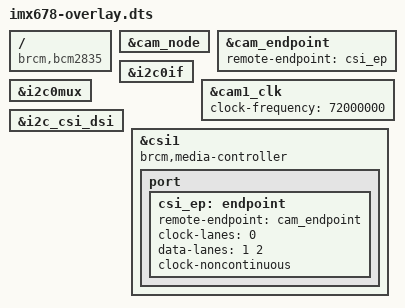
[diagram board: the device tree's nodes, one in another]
// SPDX-License-Identifier: GPL-2.0-only
// Definitions for imx678 camera module on VC I2C bus
/dts-v1/;
/plugin/;

#include <dt-bindings/gpio/gpio.h>

/{
	compatible = "brcm,bcm2835";

    fragment@2 {
		target = <&i2c0if>;
		__overlay__ {
			status = "okay";
		};
	};

    clk_frag: fragment@3 {
		target = <&cam1_clk>;
		__overlay__ {
			clock-frequency = <72000000>;
			status = "okay";
		};
	};

    fragment@4 {
		target = <&i2c0mux>;
		__overlay__ {
			status = "okay";
		};
	};

	i2c_frag: fragment@0 {
		target = <&i2c_csi_dsi>;
		__overlay__ {
			#address-cells = <1>;
			#size-cells = <0>;
			status = "okay";

			#include "imx678.dtsi"
		};
	};

	csi_frag: fragment@1 {
		target = <&csi1>;
		csi: __overlay__ {
			status = "okay";
			brcm,media-controller;

			port{
				csi_ep: endpoint{
					remote-endpoint = <&cam_endpoint>;
					clock-lanes = <0>;
					data-lanes = <1 2>;
					clock-noncontinuous;
				};
			};
		};
	};

};

&cam_node {
	status = "okay";
};

&cam_endpoint {
	remote-endpoint = <&csi_ep>;
};
